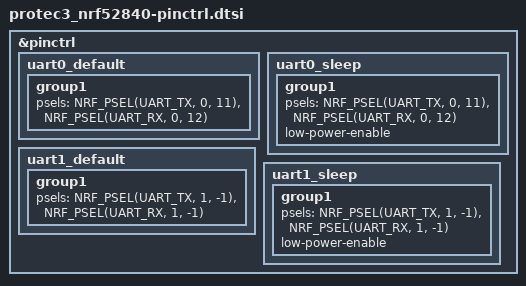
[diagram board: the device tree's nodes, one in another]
/*
 * Copyright (c) 2022 Nordic Semiconductor ASA
 *
 * SPDX-License-Identifier: LicenseRef-Nordic-5-Clause
 */

&pinctrl {
	uart0_default: uart0_default {
		group1 {
			psels = <NRF_PSEL(UART_TX, 0, 11)>,
				<NRF_PSEL(UART_RX, 0, 12)>;
		};
	};

	uart0_sleep: uart0_sleep {
		group1 {
			psels = <NRF_PSEL(UART_TX, 0, 11)>,
				<NRF_PSEL(UART_RX, 0, 12)>;
			low-power-enable;
		};
	};

	uart1_default: uart1_default {
		group1 {
			psels = <NRF_PSEL(UART_TX, 1, -1)>,
				<NRF_PSEL(UART_RX, 1, -1)>;
		};
	};

	uart1_sleep: uart1_sleep {
		group1 {
			psels = <NRF_PSEL(UART_TX, 1, -1)>,
				<NRF_PSEL(UART_RX, 1, -1)>;
			low-power-enable;
		};
	};

};
